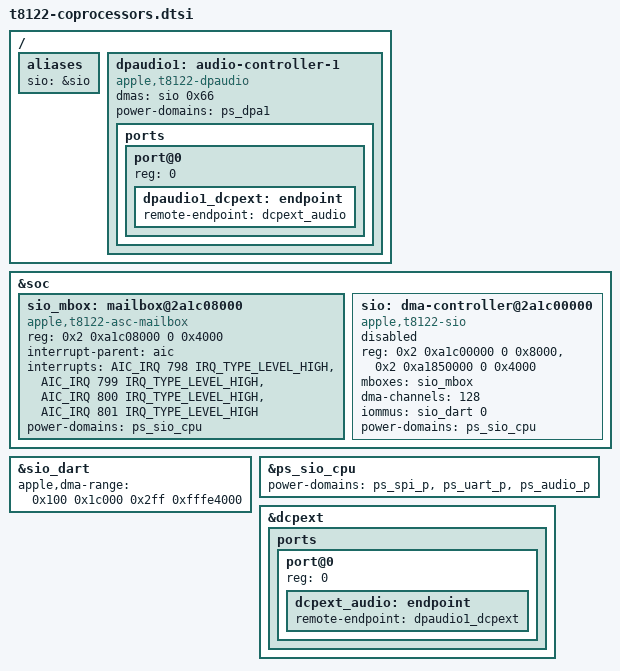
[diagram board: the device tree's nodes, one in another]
// SPDX-License-Identifier: GPL-2.0+ OR MIT
/*
 * Coprocessor interfaces; firmware handoff remains a loader job.
 *
 * SIO: iBoot preloads its firmware (ADT segment-ranges, remapped at 1 TiB as
 * on M4); the boot loader reserves it, publishes the boot tables (T6041
 * layout, as the ADT's 36-byte DMA shim records describe) and enables the
 * node, which it finds by the alias. Without such a loader the SIO stays
 * disabled and nothing else changes.
 */

/ {
	aliases {
		sio = &sio;
	};
};

&soc {
	sio_mbox: mailbox@2a1c08000 {
		compatible = "apple,t8122-asc-mailbox", "apple,asc-mailbox-v4";
		reg = <0x2 0xa1c08000 0 0x4000>;
		interrupt-parent = <&aic>;
		interrupts = <AIC_IRQ 798 IRQ_TYPE_LEVEL_HIGH>,
		             <AIC_IRQ 799 IRQ_TYPE_LEVEL_HIGH>,
		             <AIC_IRQ 800 IRQ_TYPE_LEVEL_HIGH>,
		             <AIC_IRQ 801 IRQ_TYPE_LEVEL_HIGH>;
		interrupt-names = "send-empty", "send-not-empty",
				  "recv-empty", "recv-not-empty";
		#mbox-cells = <0>;
		power-domains = <&ps_sio_cpu>;
		status = "okay";
	};

	sio: dma-controller@2a1c00000 {
		compatible = "apple,t8122-sio", "apple,sio";
		/* The ASC registers end where the mailbox starts, as on T8132. */
		reg = <0x2 0xa1c00000 0 0x8000>,
		      <0x2 0xa1850000 0 0x4000>;
		mboxes = <&sio_mbox>;
		#dma-cells = <1>;
		dma-channels = <128>;
		iommus = <&sio_dart 0>;
		power-domains = <&ps_sio_cpu>;
		status = "disabled";
	};

};

/* The boot tables sit in the window above the preloaded segments (ADT segment-ranges). */
&sio_dart {
	apple,dma-range = <0x100 0x1c000 0x2ff 0xfffe4000>;
};

/*
 * The SIO firmware drives the SPI, UART and DP audio shims (ADT device-type
 * dSPI, dUAR, dDPA), so keep their parents on while it runs.
 */
&ps_sio_cpu {
	power-domains = <&ps_spi_p>, <&ps_uart_p>, <&ps_audio_p>;
};

/*
 * DisplayPort audio over the USB-C ports, as the ADT has it: the external
 * display processor's audio is dp-audio1 (dcpext's `audio` phandle; SIO DMA
 * channel 0x66, power state DPA1). dp-audio0 belongs to the internal panel's
 * DCP, which has no audio sink, and stays off. Without a running SIO the
 * interface waits for its DMA channel.
 */
/ {
	dpaudio1: audio-controller-1 {
		compatible = "apple,t8122-dpaudio", "apple,dpaudio";
		dmas = <&sio 0x66>;
		dma-names = "tx";
		power-domains = <&ps_dpa1>;

		ports {
			#address-cells = <1>;
			#size-cells = <0>;

			port@0 {
				reg = <0>;
				dpaudio1_dcpext: endpoint {
					remote-endpoint = <&dcpext_audio>;
				};
			};
		};
	};
};

&dcpext {
	ports {
		#address-cells = <1>;
		#size-cells = <0>;

		port@0 {
			reg = <0>;
			dcpext_audio: endpoint {
				remote-endpoint = <&dpaudio1_dcpext>;
			};
		};
	};
};
